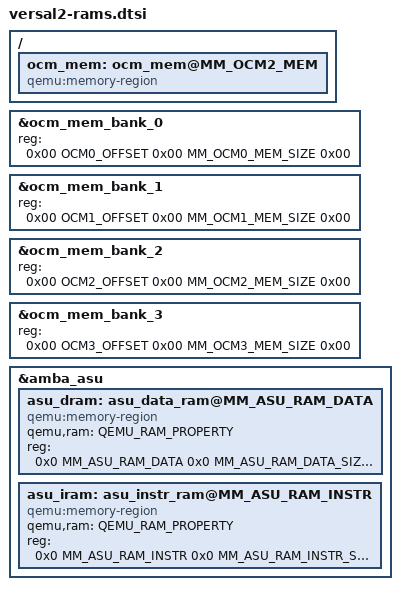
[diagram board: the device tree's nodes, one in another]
/*
 * Versal Gen 2 rams Overlay.
 * This contains the overlay that's suitable for the both QEMU
 * instances in a multi-arch PSX/PMX setup.
 *
 * Copyright (c) 2023 Advanced Micro Devices Inc.
 * All rights reserved.
 *
 * Redistribution and use in source and binary forms, with or without
 * modification, are permitted provided that the following conditions are met:
 *     * Redistributions of source code must retain the above copyright
 *       notice, this list of conditions and the following disclaimer.
 *     * Redistributions in binary form must reproduce the above copyright
 *       notice, this list of conditions and the following disclaimer in the
 *       documentation and/or other materials provided with the distribution.
 *     * Neither the name of the <organization> nor the
 *       names of its contributors may be used to endorse or promote products
 *       derived from this software without specific prior written permission.
 *
 * THIS SOFTWARE IS PROVIDED BY THE COPYRIGHT HOLDERS AND CONTRIBUTORS "AS IS" AND
 * ANY EXPRESS OR IMPLIED WARRANTIES, INCLUDING, BUT NOT LIMITED TO, THE IMPLIED
 * WARRANTIES OF MERCHANTABILITY AND FITNESS FOR A PARTICULAR PURPOSE ARE
 * DISCLAIMED. IN NO EVENT SHALL <COPYRIGHT HOLDER> BE LIABLE FOR ANY
 * DIRECT, INDIRECT, INCIDENTAL, SPECIAL, EXEMPLARY, OR CONSEQUENTIAL DAMAGES
 * (INCLUDING, BUT NOT LIMITED TO, PROCUREMENT OF SUBSTITUTE GOODS OR SERVICES;
 * LOSS OF USE, DATA, OR PROFITS; OR BUSINESS INTERRUPTION) HOWEVER CAUSED AND
 * ON ANY THEORY OF LIABILITY, WHETHER IN CONTRACT, STRICT LIABILITY, OR TORT
 * (INCLUDING NEGLIGENCE OR OTHERWISE) ARISING IN ANY WAY OUT OF THE USE OF THIS
 * SOFTWARE, EVEN IF ADVISED OF THE POSSIBILITY OF SUCH DAMAGE.
 */

/*
 * The OCM memories layout changed a bit.  Bank0-1 are mapped at the same place
 * than Versal, while Bank2-3 are mapped just below.
 *
 * 0xBBE00000 |-------|
 *	      | BANK2 |
 * 0xBBE80000 |-------|
 *	      | BANK3 |
 * 0xBBF00000 |-------|
 *	      | BANK0 |
 * 0xBBF80000 |-------|
 *	      | BANK1 |
 *	      |-------|
 */
#define OCM0_OFFSET (MM_OCM0_MEM - MM_OCM2_MEM)
#define OCM1_OFFSET (MM_OCM1_MEM - MM_OCM2_MEM)
#define OCM2_OFFSET (MM_OCM2_MEM - MM_OCM2_MEM)
#define OCM3_OFFSET (MM_OCM3_MEM - MM_OCM2_MEM)
/ {
	/delete-node/ ocm_mem@MM_OCM_MEM;
	ocm_mem: ocm_mem@MM_OCM2_MEM {
		compatible = "qemu:memory-region";
	};
	/delete-node/ xram_mem_bank_0@0x0;
	/delete-node/ xram_mem_bank_1@0x200000;
	/delete-node/ xram_mem_bank_2@0x400000;
	/delete-node/ xram_mem_bank_3@0x600000;
};

&ocm_mem_bank_0 {
	reg = <0x00 OCM0_OFFSET 0x00 MM_OCM0_MEM_SIZE 0x00>;
};

&ocm_mem_bank_1 {
	reg = <0x00 OCM1_OFFSET 0x00 MM_OCM1_MEM_SIZE 0x00>;
};

&ocm_mem_bank_2 {
	reg = <0x00 OCM2_OFFSET 0x00 MM_OCM2_MEM_SIZE 0x00>;
};

&ocm_mem_bank_3 {
	reg = <0x00 OCM3_OFFSET 0x00 MM_OCM3_MEM_SIZE 0x00>;
};

/*
 * ASU RAMS
 */
&amba_asu {
	asu_dram: asu_data_ram@MM_ASU_RAM_DATA {
		compatible = "qemu:memory-region";
		device_type = "memory";
		qemu,ram = <QEMU_RAM_PROPERTY>;
		reg = <0x0 MM_ASU_RAM_DATA 0x0 MM_ASU_RAM_DATA_SIZE 0x0>;
	};
	asu_iram: asu_instr_ram@MM_ASU_RAM_INSTR {
		compatible = "qemu:memory-region";
		device_type = "memory";
		qemu,ram = <QEMU_RAM_PROPERTY>;
		reg = <0x0 MM_ASU_RAM_INSTR 0x0 MM_ASU_RAM_INSTR_SIZE 0x0>;
	};
};
